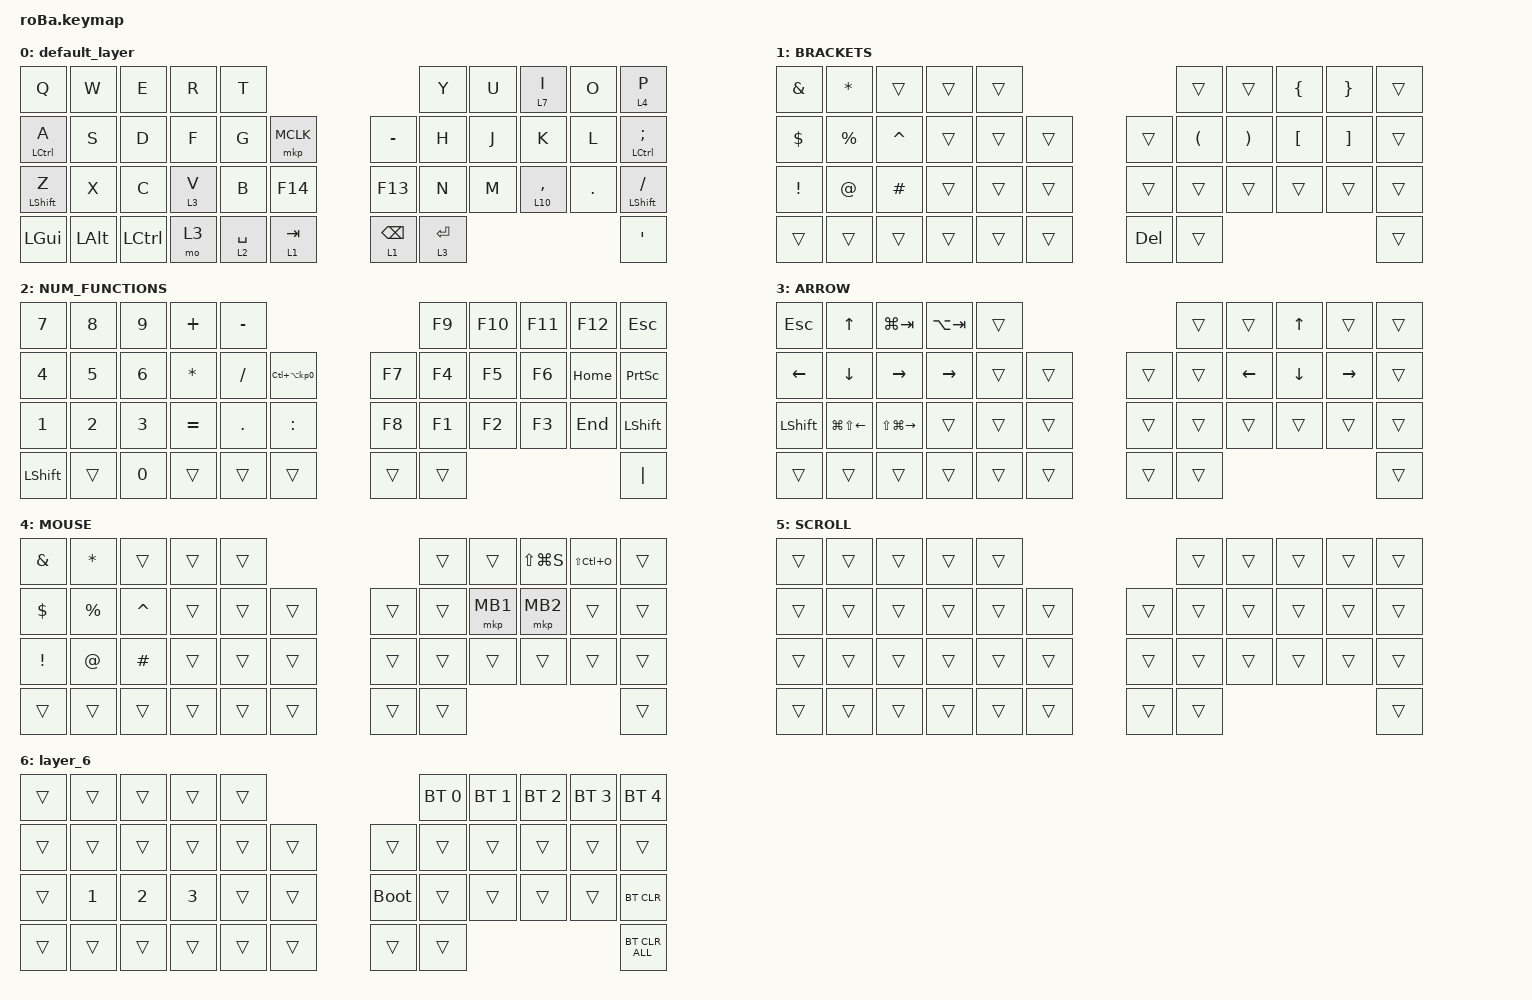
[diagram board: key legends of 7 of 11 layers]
#define ZMK_MOUSE_DEFAULT_SCRL_VAL 10

#include <behaviors.dtsi>
#include <dt-bindings/zmk/bt.h>
#include <dt-bindings/zmk/keys.h>
#include <dt-bindings/zmk/pointing.h>
#include <mouse-gesture.dtsi>

#define ZMK_POINTING_DEFAULT_SCRL_VAL 80

&mt {
    flavor = "balanced";
    quick-tap-ms = <0>;
};

/ {
    combos {
        compatible = "zmk,combos";

        mid_click {
            bindings = <&mkp MB3>;
            key-positions = <18 19>;
        };

        modroru {
            bindings = <&kp LA(LEFT_ARROW)>;
            key-positions = <17 18>;
        };

        susumu {
            bindings = <&kp LA(RIGHT_ARROW)>;
            key-positions = <19 20>;
        };
    };

    macros {
        to_layer_0: to_layer_0 {
            compatible = "zmk,behavior-macro-one-param";
            #binding-cells = <1>;
            bindings = <&to 0 &macro_param_1to1 &kp MACRO_PLACEHOLDER>;
            label = "TO_LAYER_0";
        };
    };

    behaviors {
        lt_to_layer_0: lt_to_layer_0 {
            compatible = "zmk,behavior-hold-tap";
            label = "LAYER_TAP_TO_0";
            bindings = <&mo>, <&to_layer_0>;

            #binding-cells = <2>;
            tapping-term-ms = <200>;
        };

        scroll_up_down: behavior_sensor_rotate_mouse_wheel_up_down {
            compatible = "zmk,behavior-sensor-rotate";
            #sensor-binding-cells = <0>;
            bindings = <&msc SCRL_UP>, <&msc SCRL_DOWN>;

            tap-ms = <1>;
        };

        encoder_msc_down_up: encoder_msc_down_up {
            compatible = "zmk,behavior-sensor-rotate";
            label = "ENCODER_MSC_DOWN_UP";
            #sensor-binding-cells = <0>;
            bindings = <&msc SCRL_DOWN>, <&msc SCRL_UP>;

            tap-ms = <20>;
        };
    };

    keymap {
        compatible = "zmk,keymap";

        default_layer {
            bindings = <
&kp Q             &kp W         &kp E      &kp R    &kp T                                                   &kp Y        &kp U  &lt 7 I    &kp O    &lt 4 P
&mt LCTRL A       &kp S         &kp D      &kp F    &kp G        &mkp MCLK                 &kp MINUS        &kp H        &kp J  &kp K      &kp L    &mt LCTRL SEMI
&mt LEFT_SHIFT Z  &kp X         &kp C      &lt 3 V  &kp B        &kp F14                   &kp F13          &kp N        &kp M  &lt 10 COMMA  &kp DOT  &mt LSHFT SLASH
&kp LEFT_GUI      &kp LEFT_ALT  &kp LCTRL  &mo 3    &lt 2 SPACE  &lt_to_layer_0 1 TAB      &lt 1 BACKSPACE  &lt 3 ENTER                             &kp SINGLE_QUOTE
            >;

            sensor-bindings = <&encoder_msc_down_up>;
        };

        BRACKETS {
            bindings = <
&kp AMPERSAND    &kp ASTERISK  &trans     &trans  &trans                          &trans                &trans                 &kp LEFT_BRACE    &kp RIGHT_BRACE    &trans
&kp DOLLAR       &kp PERCENT   &kp CARET  &trans  &trans  &trans      &trans      &kp LEFT_PARENTHESIS  &kp RIGHT_PARENTHESIS  &kp LEFT_BRACKET  &kp RIGHT_BRACKET  &trans
&kp EXCLAMATION  &kp AT_SIGN   &kp HASH   &trans  &trans  &trans      &trans      &trans                &trans                 &trans            &trans             &trans
&trans           &trans        &trans     &trans  &trans  &trans      &kp DELETE  &trans                                                                            &trans
            >;
        };

        NUM_FUNCTIONS {
            bindings = <
&kp NUMBER_7    &kp NUMBER_8  &kp NUMBER_9  &kp PLUS      &kp MINUS                                        &kp F9  &kp F10  &kp F11  &kp F12   &kp ESCAPE
&kp NUMBER_4    &kp NUMBER_5  &kp NUMBER_6  &kp ASTERISK  &kp SLASH   &kp LC(LA(KP_NUMBER_0))      &kp F7  &kp F4  &kp F5   &kp F6   &kp HOME  &kp PRINTSCREEN
&kp N1          &kp N2        &kp NUMBER_3  &kp EQUAL     &kp PERIOD  &kp COLON                    &kp F8  &kp F1  &kp F2   &kp F3   &kp END   &kp LSHFT
&kp LEFT_SHIFT  &trans        &kp NUMBER_0  &trans        &trans      &trans                       &trans  &trans                              &kp PIPE
            >;
        };

        ARROW {
            bindings = <
&kp ESCAPE      &kp UP_ARROW            &kp LG(TAB)              &kp LA(TAB)      &trans                      &trans  &trans          &kp UP_ARROW    &trans           &trans
&kp LEFT_ARROW  &kp DOWN_ARROW          &kp RIGHT_ARROW          &kp RIGHT_ARROW  &trans  &trans      &trans  &trans  &kp LEFT_ARROW  &kp DOWN_ARROW  &kp RIGHT_ARROW  &trans
&kp LEFT_SHIFT  &kp LG(LS(LEFT_ARROW))  &kp LS(LG(RIGHT_ARROW))  &trans           &trans  &trans      &trans  &trans  &trans          &trans          &trans           &trans
&trans          &trans                  &trans                   &trans           &trans  &trans      &trans  &trans                                                   &trans
            >;

            sensor-bindings = <&inc_dec_kp LC(PAGE_UP) LC(PAGE_DOWN)>;
        };

        MOUSE {
            bindings = <
&kp AMPERSAND    &kp ASTERISK  &trans     &trans  &trans                      &trans  &trans    &kp LS(LG(S))  &kp LS(LC(O))  &trans
&kp DOLLAR       &kp PERCENT   &kp CARET  &trans  &trans  &trans      &trans  &trans  &mkp MB1  &mkp MB2       &trans         &trans
&kp EXCLAMATION  &kp AT_SIGN   &kp HASH   &trans  &trans  &trans      &trans  &trans  &trans    &trans         &trans         &trans
&trans           &trans        &trans     &trans  &trans  &trans      &trans  &trans                                          &trans
            >;
        };

        SCROLL {
            bindings = <
&trans  &trans  &trans  &trans  &trans                      &trans  &trans  &trans  &trans  &trans
&trans  &trans  &trans  &trans  &trans  &trans      &trans  &trans  &trans  &trans  &trans  &trans
&trans  &trans  &trans  &trans  &trans  &trans      &trans  &trans  &trans  &trans  &trans  &trans
&trans  &trans  &trans  &trans  &trans  &trans      &trans  &trans                          &trans
            >;
        };

        layer_6 {
            bindings = <
&trans  &trans        &trans        &trans        &trans                           &bt BT_SEL 0  &bt BT_SEL 1  &bt BT_SEL 2  &bt BT_SEL 3  &bt BT_SEL 4
&trans  &trans        &trans        &trans        &trans  &trans      &trans       &trans        &trans        &trans        &trans        &trans
&trans  &kp NUMBER_1  &kp NUMBER_2  &kp NUMBER_3  &trans  &trans      &bootloader  &trans        &trans        &trans        &trans        &bt BT_CLR
&trans  &trans        &trans        &trans        &trans  &trans      &trans       &trans                                                  &bt BT_CLR_ALL
            >;
        };

        SCROLL2 {
            bindings = <
&trans  &trans  &trans  &trans  &trans                      &trans  &trans  &trans  &trans  &trans
&trans  &trans  &trans  &trans  &trans  &trans      &trans  &trans  &trans  &trans  &trans  &trans
&trans  &trans  &trans  &trans  &trans  &trans      &trans  &trans  &trans  &trans  &trans  &trans
&trans  &trans  &trans  &trans  &trans  &trans      &trans  &trans
            >;
        };

        AML {
            bindings = <
&trans  &trans  &trans  &trans  &trans                      &trans  &trans    &trans    &trans  &trans
&trans  &trans  &trans  &trans  &trans  &trans      &trans  &trans  &mkp MB1  &mkp MB2  &tog 9  &trans
&trans  &trans  &trans  &trans  &trans  &trans      &to 0   &trans  &trans    &trans    &trans  &trans
&trans  &trans  &trans  &trans  &trans  &trans      &trans  &trans
            >;
        };

        SNIPE {
            bindings = <
&trans  &trans  &trans  &trans  &trans                      &trans  &trans    &trans    &trans  &trans
&trans  &trans  &trans  &trans  &trans  &trans      &trans  &trans  &mkp MB1  &mkp MB2  &tog 9  &trans
&trans  &trans  &trans  &trans  &trans  &trans      &trans  &trans  &trans    &trans    &trans  &trans
&trans  &trans  &trans  &trans  &trans  &trans      &trans  &trans
            >;
        };

        GESTURE {
            bindings = <
&trans  &trans  &trans  &trans  &trans                      &trans  &trans  &trans  &trans  &trans
&trans  &trans  &trans  &trans  &trans  &trans      &trans  &trans  &trans  &trans  &trans  &trans
&trans  &trans  &trans  &trans  &trans  &trans      &trans  &trans  &trans  &trans  &trans  &trans
&trans  &trans  &trans  &trans  &trans  &trans      &trans  &trans
            >;
        };
    };
};
